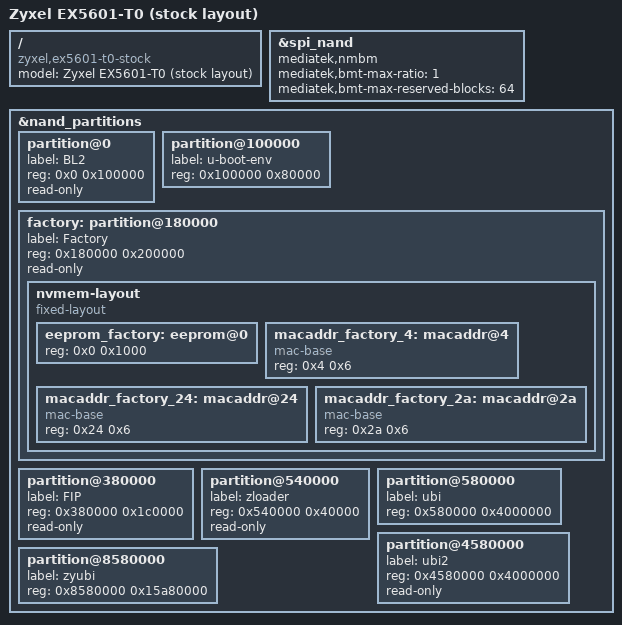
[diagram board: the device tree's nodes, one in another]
// SPDX-License-Identifier: (GPL-2.0 OR MIT)
/*
 * Copyright (C) 2021 MediaTek Inc.
 * Author: Sam.Shih <sam.shih@mediatek.com>
 */

/dts-v1/;
#include "mt7986a-zyxel-ex5601-t0-common.dtsi"

/ {
	model = "Zyxel EX5601-T0 (stock layout)";
	compatible = "zyxel,ex5601-t0-stock", "mediatek,mt7986a";
};

&spi_nand {
	mediatek,nmbm;
	mediatek,bmt-max-ratio = <1>;
	mediatek,bmt-max-reserved-blocks = <64>;
};

&nand_partitions {

	partition@0 {
		label = "BL2";
		reg = <0x0 0x100000>;
		read-only;
	};

	partition@100000 {
		label = "u-boot-env";
		reg = <0x100000 0x80000>;
	};

	factory: partition@180000 {
		label = "Factory";
		reg = <0x180000 0x200000>;
		read-only;

		nvmem-layout {
			compatible = "fixed-layout";
			#address-cells = <1>;
			#size-cells = <1>;

			eeprom_factory: eeprom@0 {
				#size-cells = <1>;
				reg = <0x0 0x1000>;
			};

			macaddr_factory_4: macaddr@4 {
				compatible = "mac-base";
				reg = <0x4 0x6>;
				#nvmem-cell-cells = <1>;
			};

			macaddr_factory_24: macaddr@24 {
				compatible = "mac-base";
				reg = <0x24 0x6>;
				#nvmem-cell-cells = <1>;
			};

			macaddr_factory_2a: macaddr@2a {
				compatible = "mac-base";
				reg = <0x2a 0x6>;
				#nvmem-cell-cells = <1>;
			};
		};
	};

	partition@380000 {
		label = "FIP";
		reg = <0x380000 0x1c0000>;
		read-only;
	};

	partition@540000 {
		label = "zloader";
		reg = <0x540000 0x40000>;
		read-only;
	};

	partition@580000 {
		label = "ubi";
		reg = <0x580000 0x4000000>;
	};

	partition@4580000 {
		label = "ubi2";
		reg = <0x4580000 0x4000000>;
		read-only;
	};

	partition@8580000 {
		label = "zyubi";
		reg = <0x8580000 0x15a80000>;
	};
};
